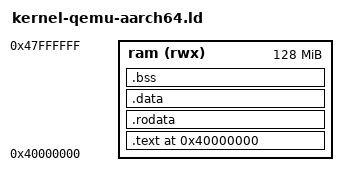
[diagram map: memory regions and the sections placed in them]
ENTRY(_start)

MEMORY
{
    ram (rwx) : ORIGIN = 0x40000000, LENGTH = 128M
}

SECTIONS
{
    . = 0x40000000;

    .text : {
        KEEP(*(.text.boot))
        *(.text .text.*)
    } > ram

    .rodata : {
        *(.rodata .rodata.*)
    } > ram

    .data : {
        *(.data .data.*)
    } > ram

    .bss : {
        . = ALIGN(16);
        __bss_start = .;
        *(.bss .bss.*)
        *(COMMON)
        __bss_end = .;
    } > ram

    . = ALIGN(16);
    . += 65536; /* 64KB Stack */
    __stack_top = .;
}
